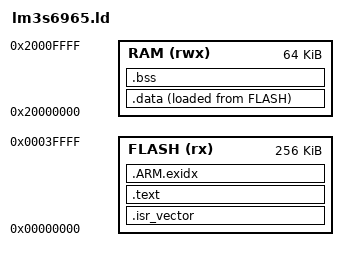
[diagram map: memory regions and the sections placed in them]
/* Linker script for TI Stellaris LM3S6965 (Cortex-M3)
 * Flash: 256 KB @ 0x00000000
 * SRAM :  64 KB @ 0x20000000
 */
ENTRY(Reset_Handler)

MEMORY
{
    FLASH (rx)  : ORIGIN = 0x00000000, LENGTH = 256K
    RAM   (rwx) : ORIGIN = 0x20000000, LENGTH = 64K
}

_estack = ORIGIN(RAM) + LENGTH(RAM);   /* initial main stack pointer */

SECTIONS
{
    .isr_vector :
    {
        KEEP(*(.isr_vector))
    } > FLASH

    .text :
    {
        *(.text*)
        *(.rodata*)
        . = ALIGN(4);
        _etext = .;
    } > FLASH

    .ARM.exidx :
    {
        *(.ARM.exidx*)
    } > FLASH

    _sidata = LOADADDR(.data);

    .data :
    {
        _sdata = .;
        *(.data*)
        . = ALIGN(4);
        _edata = .;
    } > RAM AT > FLASH

    .bss (NOLOAD) :
    {
        _sbss = .;
        *(.bss*)
        *(COMMON)
        . = ALIGN(4);
        _ebss = .;
    } > RAM
}
